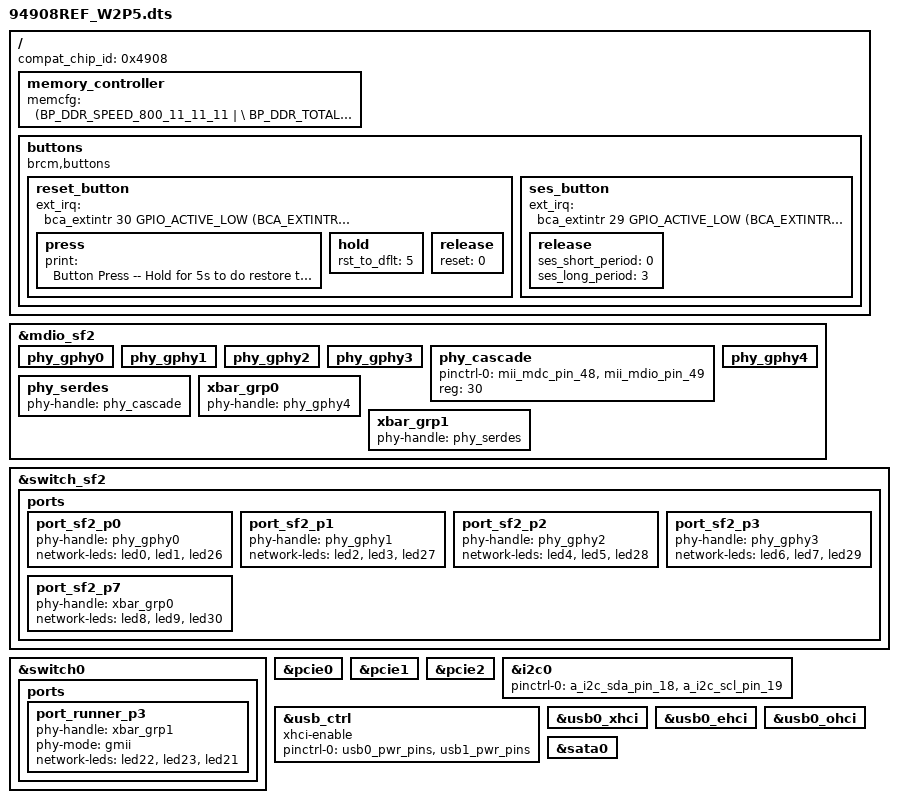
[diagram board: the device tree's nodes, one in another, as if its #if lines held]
#include "4908.dtsi"
#include "94906REF_leds.dtsi"

/ {
	compat_chip_id = <0x4908>;
    memory_controller {
        memcfg = <(BP_DDR_SPEED_800_11_11_11 | \
                   BP_DDR_TOTAL_SIZE_1024MB  | \
                   BP_DDR_DEVICE_WIDTH_16    | \
                   BP_DDR_TOTAL_WIDTH_32BIT  | \
                   BP_DDR_SSC_CONFIG_1)>;
    };

	buttons {
		compatible = "brcm,buttons";
		reset_button {
			ext_irq = <&bca_extintr 30 GPIO_ACTIVE_LOW (BCA_EXTINTR_TYPE_LOW_LEVEL | BCA_EXTINTR_TYPE_SENSE_LEVEL)>;
			press {
				print = "Button Press -- Hold for 5s to do restore to default";
			};
			hold {
				rst_to_dflt = <5>;
			};
			release {
				reset = <0>;
			};	
		};
		ses_button {
			ext_irq = <&bca_extintr 29 GPIO_ACTIVE_LOW (BCA_EXTINTR_TYPE_LOW_LEVEL | BCA_EXTINTR_TYPE_SENSE_LEVEL)>;
			release {
				ses_short_period = <0>;
				ses_long_period = <3>;
			};
		};
	};
};

&mdio_sf2 {
        /* Port PHY mapping:
            port_runner_p0  <-->  port_sf2_p8 -###- port_sf2_p0 <------------------> phy_gphy0
            port_runner_p1  <-->  port_sf2_p5 -# #- port_sf2_p1 <------------------> phy_gphy1
            port_runner_p2  <-->  port_sf2_p4 -# #- port_sf2_p2 <------------------> phy_gphy2
                                               # #- port_sf2_p3 <------------------> phy_gphy3
                                               ###- port_sf2_p7 <--> xbar_grp0 -+-+- phy_gphy4
                                                 port_runner_p3 <--> xbar_grp1 -+-+- phy_serdes - phy_cascade
         */
	/* PHYs directly connected to SF2 */
	phy_gphy0 {
		status = "okay";
	};
	phy_gphy1 {
		status = "okay";
	};
	phy_gphy2 {
		status = "okay";
	};
	phy_gphy3 {
		status = "okay";
	};

	/* Cascade PHY */
	phy_cascade {
		pinctrl-names = "default";
		pinctrl-0 = <&mii_mdc_pin_48 &mii_mdio_pin_49>;
		reg = <30>;
		status = "okay";
	};
	
	/* PHYs connected to crossbar */
	phy_gphy4 {
		status = "okay";
	};
	phy_serdes {
		phy-handle = <&phy_cascade>;
		status = "okay";
	};

	/* Crossbar groups */
	xbar_grp0 {
		phy-handle = <&phy_gphy4>;
		status = "okay";
	};
	xbar_grp1 {
		phy-handle = <&phy_serdes>;
		status = "okay";
	};
};

&switch_sf2 {
	ports {
		port_sf2_p0 {
			phy-handle = <&phy_gphy0>;
			network-leds = <&led0 &led1 &led26>;
			status = "okay";
		};

		port_sf2_p1 {
			phy-handle = <&phy_gphy1>;
			network-leds = <&led2 &led3 &led27>;
			status = "okay";
		};

		port_sf2_p2 {
			phy-handle = <&phy_gphy2>;
			network-leds = <&led4 &led5 &led28>;
			status = "okay";
		};

		port_sf2_p3 {
			phy-handle = <&phy_gphy3>;
			network-leds = <&led6 &led7 &led29>;
			status = "okay";
		};

		port_sf2_p7 {
			phy-handle = <&xbar_grp0>;
			network-leds = <&led8 &led9 &led30>;
			status = "okay";
		};

	};
};

&switch0 {
	ports {
		
		port_runner_p3 {
			phy-handle = <&xbar_grp1>;
			phy-mode = "gmii";
			network-leds = <&led22 &led23 &led21>;
			status = "okay";
		};
	};
};

#if defined(CONFIG_BCM_PCIE_HCD) || defined(CONFIG_BCM_PCIE_HCD_MODULE)
&pcie0 {
	status = "okay";
};
&pcie1 {
	status = "okay";
};
&pcie2 {
	status = "okay";
};
#endif //#if defined(CONFIG_BCM_PCIE_HCD) || defined(CONFIG_BCM_PCIE_HCD_MODULE)

&i2c0 {
	pinctrl-names = "default";
	pinctrl-0 = <&a_i2c_sda_pin_18 &a_i2c_scl_pin_19>;
	status = "okay";
};

&usb_ctrl {
	status = "okay";
	xhci-enable;
	pinctrl-names = "default";
	pinctrl-0 = <&usb0_pwr_pins &usb1_pwr_pins>;
};

&usb0_xhci {
	status = "okay";
};

&usb0_ehci {
	status = "okay";
};

&usb0_ohci {
	status = "okay";
};

&sata0 {
	status = "okay";
};
